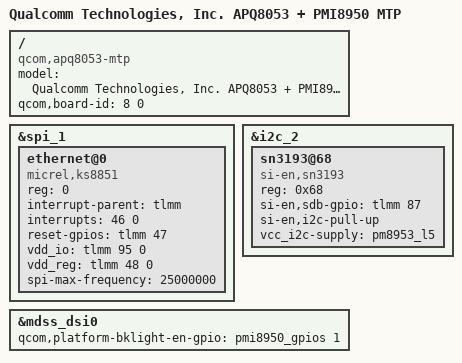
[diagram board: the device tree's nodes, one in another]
/*
 * Copyright (c) 2015-2017, The Linux Foundation. All rights reserved.
 *
 * This program is free software; you can redistribute it and/or modify
 * it under the terms of the GNU General Public License version 2 and
 * only version 2 as published by the Free Software Foundation.
 *
 * This program is distributed in the hope that it will be useful,
 * but WITHOUT ANY WARRANTY; without even the implied warranty of
 * MERCHANTABILITY or FITNESS FOR A PARTICULAR PURPOSE.  See the
 * GNU General Public License for more details.
 */

/dts-v1/;

#include "apq8053.dtsi"
#include "msm-pmi8950.dtsi"
#include "msm8953-mtp.dtsi"
#include "msm8953-pmi8950.dtsi"
#include "msm8953-camera-sensor-mtp.dtsi"

/ {
	model = "Qualcomm Technologies, Inc. APQ8053 + PMI8950 MTP";
	compatible = "qcom,apq8053-mtp", "qcom,apq8053", "qcom,mtp";
	qcom,board-id= <8 0>;
};

&spi_1 {
	ethernet@0 {
		status = "okay";
		compatible = "micrel,ks8851";
		reg = <0>;
		interrupt-parent = <&tlmm>;
		interrupts = <46 0>;
		reset-gpios = <&tlmm 47 0>;
		vdd_io = <&tlmm 95 0>;
		vdd_reg = <&tlmm 48 0>;
		spi-max-frequency = <25000000>;
	};
};

&i2c_2 {
	sn3193@68 {
		compatible = "si-en,sn3193";
		reg = <0x68>;
		si-en,sdb-gpio = <&tlmm 87 0x00>;
		si-en,i2c-pull-up;
		vcc_i2c-supply = <&pm8953_l5>;
	};
};

&mdss_dsi0 {
	qcom,platform-bklight-en-gpio = <&pmi8950_gpios 1 0>; /* use pmi8952 gpio1 */
};
